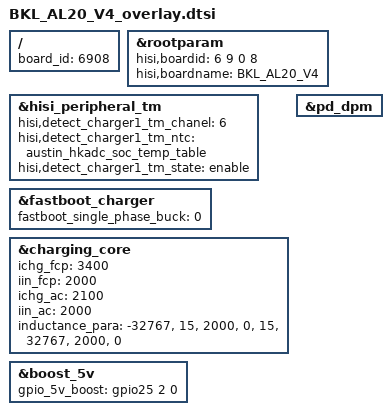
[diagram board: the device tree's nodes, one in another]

/**
 * Copyright (C) 2014 Hisilicon Ltd.
 *
 *  This program is free software; you can redistribute it and/or modify
 *  it under the terms of the GNU General Public License version 2 as
 *  publishhed by the Free Software Foundation.
 */

/include/ "BKL_AL20_V3_overlay.dtsi"

/ {
	board_id = <6908>;
};

&rootparam {
    hisi,boardid = <6 9 0 8>;
    hisi,boardname = "BKL_AL20_V4";
};

	&hisi_peripheral_tm {
			hisi,detect_charger1_tm_chanel = <6>;
			hisi,detect_charger1_tm_ntc = "austin_hkadc_soc_temp_table";
			hisi,detect_charger1_tm_state = "enable";

			status = "ok";
	};

	&fastboot_charger {
		fastboot_single_phase_buck = <0>;
		status = "ok";
	};
	&charging_core {
		status = "ok";
		ichg_fcp = <3400>;
		iin_fcp = <2000>;
		ichg_ac = <2100>;
		iin_ac = <2000>;
		inductance_para =
			"-32767", "15", "2000", "0",
			"15", "32767", "2000", "0";
	};
	&pd_dpm {
		status = "ok";
	};
	&boost_5v {
		gpio_5v_boost = <&gpio25 2 0>;
		status = "ok";
	};
